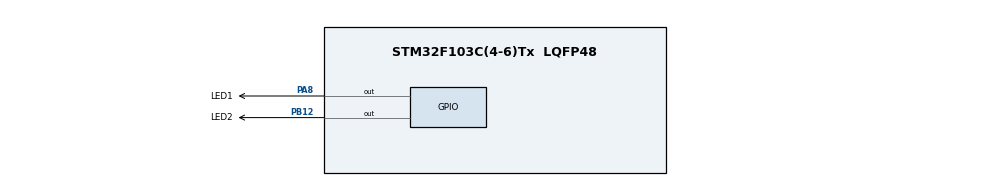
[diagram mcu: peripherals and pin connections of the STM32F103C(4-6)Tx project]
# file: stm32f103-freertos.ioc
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FREERTOS.Tasks01=blink01,24,128,StartBlink01,Default,NULL,Dynamic,NULL,NULL;blink02,24,128,StartBlink02,Default,NULL,Dynamic,NULL,NULL
Mcu.Family=STM32F1
Mcu.Name=STM32F103C(4-6)Tx
Mcu.Package=LQFP48
NVIC.PriorityGroup=NVIC_PRIORITYGROUP_4
NVIC.TIM3_IRQn=true\:15\:0\:false\:false\:true\:false\:false\:true\:true
NVIC.TimeBase=TIM3_IRQn
NVIC.TimeBaseIP=TIM3
PA8.GPIO_Label=LED1
PA8.Signal=GPIO_Output
PB12.GPIO_Label=LED2
PB12.Signal=GPIO_Output
ProjectManager.HeapSize=0x200
ProjectManager.StackSize=0x400
ProjectManager.TargetToolchain=Makefile
RCC.APB1Freq_Value=8000000
RCC.APB2Freq_Value=8000000
VP_FREERTOS_VS_CMSIS_V2.Mode=CMSIS_V2
VP_SYS_VS_ND.Mode=No_Debug
VP_SYS_VS_tim3.Mode=TIM3
board=custom

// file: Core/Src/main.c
/* USER CODE BEGIN Header */
/**
  ******************************************************************************
  * @file           : main.c
  * @brief          : Main program body
  ******************************************************************************
  * @attention
  *
  * Copyright (c) 2023 STMicroelectronics.
  * All rights reserved.
  *
  * This software is licensed under terms that can be found in the LICENSE file
  * in the root directory of this software component.
  * If no LICENSE file comes with this software, it is provided AS-IS.
  *
  ******************************************************************************
  */
/* USER CODE END Header */
#include "main.h"
#include "cmsis_os.h"

/* Definitions for blink01 */
osThreadId_t blink01Handle;
const osThreadAttr_t blink01_attributes = {
  .name = "blink01",
  .stack_size = 128 * 4,
  .priority = (osPriority_t) osPriorityNormal,
};
/* Definitions for blink02 */
osThreadId_t blink02Handle;
const osThreadAttr_t blink02_attributes = {
  .name = "blink02",
  .stack_size = 128 * 4,
  .priority = (osPriority_t) osPriorityNormal,
};

void SystemClock_Config(void);
static void MX_GPIO_Init(void);
void StartBlink01(void *argument);
void StartBlink02(void *argument);

int main(void)
{

  /* MCU Configuration--------------------------------------------------------*/

  /* Reset of all peripherals, Initializes the Flash interface and the Systick. */
  HAL_Init();

  /* Configure the system clock */
  SystemClock_Config();

  /* Initialize all configured peripherals */
  MX_GPIO_Init();

  /* Init scheduler */
  osKernelInitialize();

  /* Create the thread(s) */
  /* creation of blink01 */
  blink01Handle = osThreadNew(StartBlink01, NULL, &blink01_attributes);

  /* creation of blink02 */
  blink02Handle = osThreadNew(StartBlink02, NULL, &blink02_attributes);

  /* Start scheduler */
  osKernelStart();

  /* We should never get here as control is now taken by the scheduler */
  /* Infinite loop */
  while (1)
  {

  }
}

void SystemClock_Config(void)
{
  RCC_OscInitTypeDef RCC_OscInitStruct = {0};
  RCC_ClkInitTypeDef RCC_ClkInitStruct = {0};

  /** Initializes the RCC Oscillators according to the specified parameters
  * in the RCC_OscInitTypeDef structure.
  */
  RCC_OscInitStruct.OscillatorType = RCC_OSCILLATORTYPE_HSI;
  RCC_OscInitStruct.HSIState = RCC_HSI_ON;
  RCC_OscInitStruct.HSICalibrationValue = RCC_HSICALIBRATION_DEFAULT;
  RCC_OscInitStruct.PLL.PLLState = RCC_PLL_NONE;
  if (HAL_RCC_OscConfig(&RCC_OscInitStruct) != HAL_OK)
  {
    Error_Handler();
  }

  /** Initializes the CPU, AHB and APB buses clocks
  */
  RCC_ClkInitStruct.ClockType = RCC_CLOCKTYPE_HCLK|RCC_CLOCKTYPE_SYSCLK
                              |RCC_CLOCKTYPE_PCLK1|RCC_CLOCKTYPE_PCLK2;
  RCC_ClkInitStruct.SYSCLKSource = RCC_SYSCLKSOURCE_HSI;
  RCC_ClkInitStruct.AHBCLKDivider = RCC_SYSCLK_DIV1;
  RCC_ClkInitStruct.APB1CLKDivider = RCC_HCLK_DIV1;
  RCC_ClkInitStruct.APB2CLKDivider = RCC_HCLK_DIV1;

  if (HAL_RCC_ClockConfig(&RCC_ClkInitStruct, FLASH_LATENCY_0) != HAL_OK)
  {
    Error_Handler();
  }
}

static void MX_GPIO_Init(void)
{
  GPIO_InitTypeDef GPIO_InitStruct = {0};

  /* GPIO Ports Clock Enable */
  __HAL_RCC_GPIOB_CLK_ENABLE();
  __HAL_RCC_GPIOA_CLK_ENABLE();

  /*Configure GPIO pin Output Level */
  HAL_GPIO_WritePin(LED2_GPIO_Port, LED2_Pin, GPIO_PIN_RESET);

  /*Configure GPIO pin Output Level */
  HAL_GPIO_WritePin(LED1_GPIO_Port, LED1_Pin, GPIO_PIN_RESET);

  /*Configure GPIO pin : LED2_Pin */
  GPIO_InitStruct.Pin = LED2_Pin;
  GPIO_InitStruct.Mode = GPIO_MODE_OUTPUT_PP;
  GPIO_InitStruct.Pull = GPIO_NOPULL;
  GPIO_InitStruct.Speed = GPIO_SPEED_FREQ_LOW;
  HAL_GPIO_Init(LED2_GPIO_Port, &GPIO_InitStruct);

  /*Configure GPIO pin : LED1_Pin */
  GPIO_InitStruct.Pin = LED1_Pin;
  GPIO_InitStruct.Mode = GPIO_MODE_OUTPUT_PP;
  GPIO_InitStruct.Pull = GPIO_NOPULL;
  GPIO_InitStruct.Speed = GPIO_SPEED_FREQ_LOW;
  HAL_GPIO_Init(LED1_GPIO_Port, &GPIO_InitStruct);

}

void StartBlink01(void *argument)
{
  /* USER CODE BEGIN 5 */
  /* Infinite loop */
  for(;;)
  {
    HAL_GPIO_TogglePin(LED1_GPIO_Port, LED1_Pin);
    osDelay(500);
  }
  /* USER CODE END 5 */
}

void StartBlink02(void *argument)
{
  /* USER CODE BEGIN StartBlink02 */
  /* Infinite loop */
  for(;;)
  {
    HAL_GPIO_TogglePin(LED2_GPIO_Port, LED2_Pin);
    osDelay(600);
  }
  /* USER CODE END StartBlink02 */
}

void HAL_TIM_PeriodElapsedCallback(TIM_HandleTypeDef *htim)
{
  if (htim->Instance == TIM3) {
    HAL_IncTick();
  }
}

void Error_Handler(void)
{
  __disable_irq();
  while (1)
  {
  }
}
